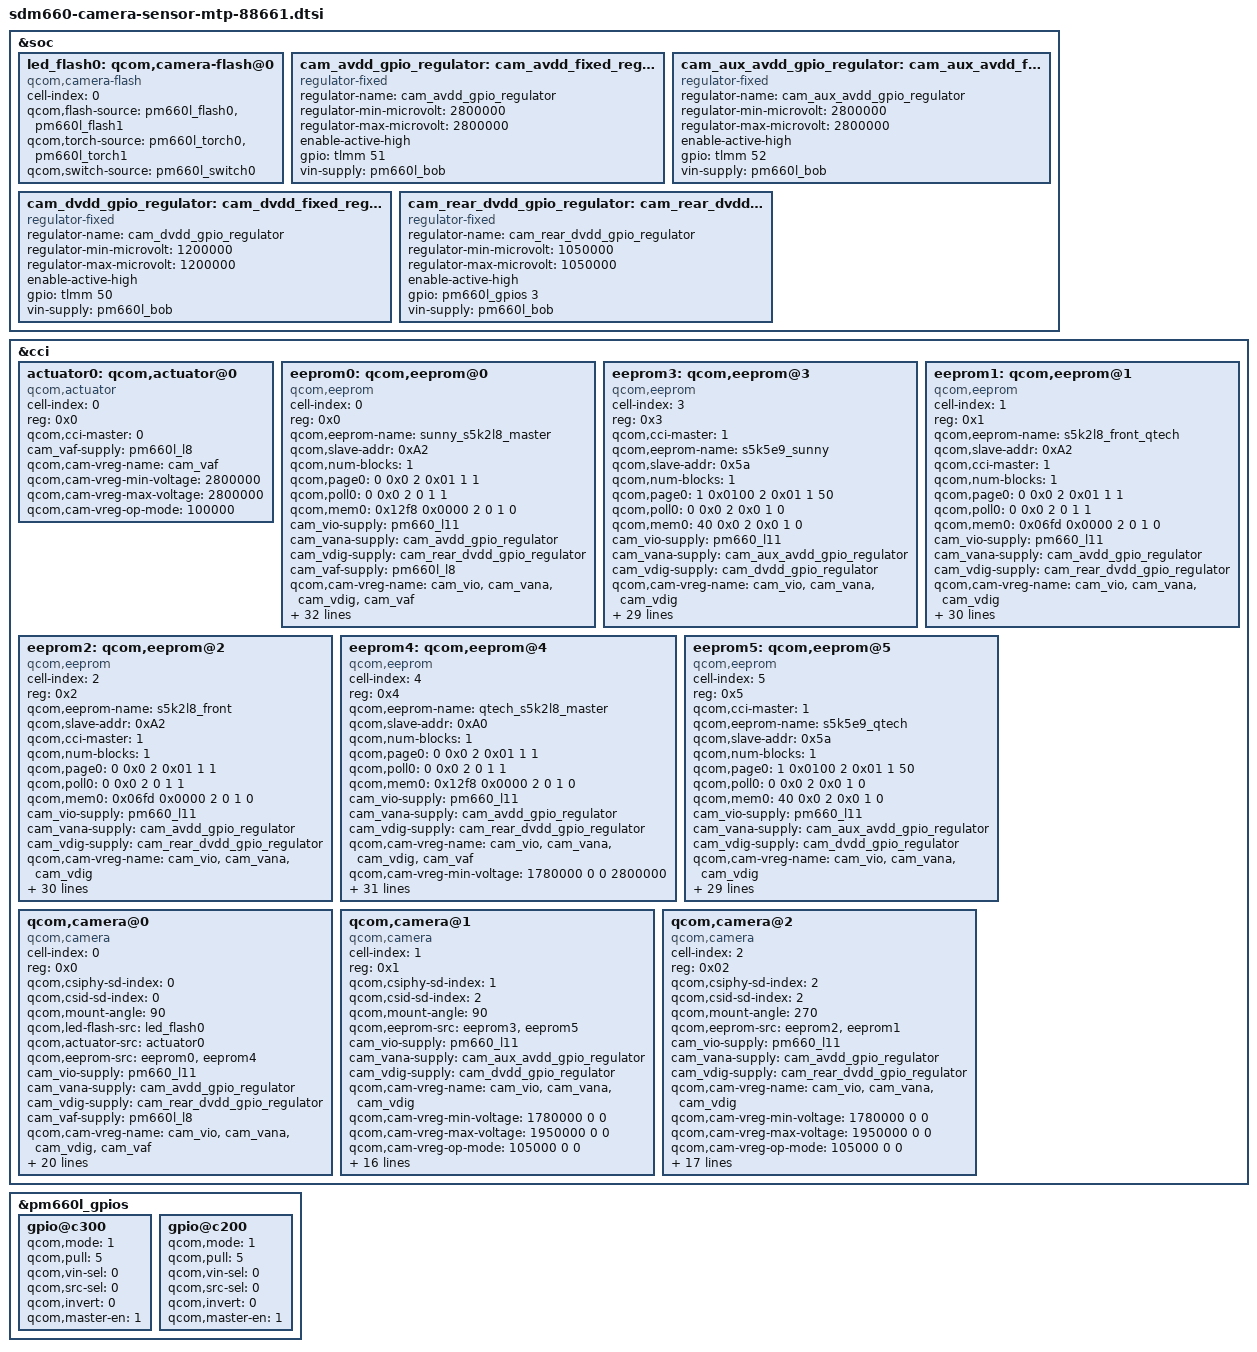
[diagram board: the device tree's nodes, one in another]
/*
 * Copyright (c) 2016-2017, The Linux Foundation. All rights reserved.
 *
 * This program is free software; you can redistribute it and/or modify
 * it under the terms of the GNU General Public License version 2 and
 * only version 2 as published by the Free Software Foundation.
 *
 * This program is distributed in the hope that it will be useful,
 * but WITHOUT ANY WARRANTY; without even the implied warranty of
 * MERCHANTABILITY or FITNESS FOR A PARTICULAR PURPOSE.  See the
 * GNU General Public License for more details.
 */
&soc {
	led_flash0: qcom,camera-flash@0 {
		cell-index = <0>;
		compatible = "qcom,camera-flash";
		qcom,flash-source = <&pm660l_flash0 &pm660l_flash1>;
		qcom,torch-source = <&pm660l_torch0 &pm660l_torch1>;
		qcom,switch-source = <&pm660l_switch0>;
		status = "ok";
	};
	cam_avdd_gpio_regulator: cam_avdd_fixed_regulator {
		compatible = "regulator-fixed";
		regulator-name = "cam_avdd_gpio_regulator";
		regulator-min-microvolt = <2800000>;
		regulator-max-microvolt = <2800000>;
		enable-active-high;
		gpio = <&tlmm 51 0>;
		vin-supply = <&pm660l_bob>;
	};

	cam_aux_avdd_gpio_regulator: cam_aux_avdd_fixed_regulator {
		compatible = "regulator-fixed";
		regulator-name = "cam_aux_avdd_gpio_regulator";
		regulator-min-microvolt = <2800000>;
		regulator-max-microvolt = <2800000>;
		enable-active-high;
		gpio = <&tlmm 52 0>;
		vin-supply = <&pm660l_bob>;
	};
	cam_dvdd_gpio_regulator: cam_dvdd_fixed_regulator {
		compatible = "regulator-fixed";
		regulator-name = "cam_dvdd_gpio_regulator";
		regulator-min-microvolt = <1200000>;
		regulator-max-microvolt = <1200000>;
		enable-active-high;
		gpio = <&tlmm 50 0>;
		vin-supply = <&pm660l_bob>;
	};

	cam_rear_dvdd_gpio_regulator: cam_rear_dvdd_fixed_regulator {
		compatible = "regulator-fixed";
		regulator-name = "cam_rear_dvdd_gpio_regulator";
		regulator-min-microvolt = <1050000>;
		regulator-max-microvolt = <1050000>;
		enable-active-high;
		gpio = <&pm660l_gpios 3 0>;
		vin-supply = <&pm660l_bob>;
	};
};

&cci {
	actuator0: qcom,actuator@0 {
		cell-index = <0>;
		reg = <0x0>;
		compatible = "qcom,actuator";
		qcom,cci-master = <0>;
		cam_vaf-supply = <&pm660l_l8>;
		qcom,cam-vreg-name = "cam_vaf";
		qcom,cam-vreg-min-voltage = <2800000>;
		qcom,cam-vreg-max-voltage = <2800000>;		
		qcom,cam-vreg-op-mode = <100000>;
	};

#if 0
	actuator1: qcom,actuator@1 {
		cell-index = <1>;
		reg = <0x1>;
		compatible = "qcom,actuator";
		qcom,cci-master = <1>;
		cam_vaf-supply = <&cam_actuator_regulator>;
		qcom,cam-vreg-name = "cam_vaf";
		qcom,cam-vreg-min-voltage = <3600000>;
		qcom,cam-vreg-max-voltage = <3600000>;
		qcom,cam-vreg-op-mode = <0>;
	};

	actuator2: qcom,actuator@2 {
		cell-index = <2>;
		reg = <0x2>;
		compatible = "qcom,actuator";
		qcom,cci-master = <1>;
		cam_vaf-supply = <&cam_actuator_regulator>;
		qcom,cam-vreg-name = "cam_vaf";
		qcom,cam-vreg-min-voltage = <3600000>;
		qcom,cam-vreg-max-voltage = <3600000>;
		qcom,cam-vreg-op-mode = <0>;
	};

	ois0: qcom,ois@0 {
		cell-index = <0>;
		reg = <0x0>;
		compatible = "qcom,ois";
		qcom,cci-master = <0>;
		cam_vaf-supply = <&cam_actuator_regulator>;
		qcom,cam-vreg-name = "cam_vaf";
		qcom,cam-vreg-min-voltage = <3600000>;
		qcom,cam-vreg-max-voltage = <3600000>;
		qcom,cam-vreg-op-mode = <0>;
		status = "disabled";
	};

	tof0: qcom,tof@29{
		cell-index = <0>;
		reg = <0x29>;
		compatible = "st,stmvl53l0";
		qcom,cci-master = <0>;
		cam_laser-supply = <&cam_actuator_regulator>;
		qcom,cam-vreg-name =  "cam_laser";
		qcom,cam-vreg-min-voltage = <3600000>;
		qcom,cam-vreg-max-voltage = <3600000>;
		pinctrl-names = "cam_default", "cam_suspend";
		pinctrl-0 = <&cam_tof_active>;
		pinctrl-1 = <&cam_tof_suspend>;
		stm,irq-gpio = <&tlmm 45  0x2008>;
		gpios = <&tlmm 42 0>;
		qcom,gpio-req-tbl-num = <0>;
		qcom,gpio-req-tbl-flags = <0>;
		qcom,gpio-req-tbl-label = "RNG_EN";
	};

	eeprom0: qcom,eeprom@0 {
		cell-index = <0>;
		reg = <0>;
		compatible = "qcom,eeprom";
		cam_vio-supply = <&pm660_l11>;
		cam_vana-supply = <&cam_avdd_gpio_regulator>;
		cam_vdig-supply = <&cam_rear_dvdd_gpio_regulator>;
		qcom,cam-vreg-name = "cam_vio", "cam_vana", "cam_vdig";
		qcom,cam-vreg-min-voltage = <1780000 0 0>;
		qcom,cam-vreg-max-voltage = <1950000 0 0>;
		qcom,cam-vreg-op-mode = <105000 0 0>;
		qcom,gpio-no-mux = <0>;
		pinctrl-names = "cam_default", "cam_suspend";
		pinctrl-0 = <&cam_sensor_mclk0_active
				&cam_sensor_rear_active
				&cam_actuator_vaf_active>;
		pinctrl-1 = <&cam_sensor_mclk0_suspend
				&cam_sensor_rear_suspend
				&cam_actuator_vaf_suspend>;
		gpios = <&tlmm 32 0>,
			<&tlmm 46 0>,
			<&tlmm 50 0>;
		qcom,gpio-reset = <1>;
		qcom,gpio-vaf = <2>;
		qcom,gpio-req-tbl-num = <0 1 2>;
		qcom,gpio-req-tbl-flags = <1 0 0>;
		qcom,gpio-req-tbl-label = "CAMIF_MCLK0",
					"CAM_RESET0",
					"CAM_VAF";
		qcom,sensor-position = <0>;
		qcom,sensor-mode = <0>;
		qcom,cci-master = <0>;
		status = "ok";
		clocks = <&clock_mmss MCLK0_CLK_SRC>,
				<&clock_mmss MMSS_CAMSS_MCLK0_CLK>;
		clock-names = "cam_src_clk", "cam_clk";
		qcom,clock-rates = <24000000 0>;
	};

	eeprom1: qcom,eeprom@1 {
		cell-index = <1>;
		reg = <0x1>;
		compatible = "qcom,eeprom";
		cam_vio-supply = <&pm660_l11>;
		cam_vana-supply = <&cam_avdd_gpio_regulator>;
		cam_vdig-supply = <&cam_dvdd_gpio_regulator>;
		qcom,cam-vreg-name = "cam_vio", "cam_vana", "cam_vdig";
		qcom,cam-vreg-min-voltage = <1780000 0 0>;
		qcom,cam-vreg-max-voltage = <1950000 0 0>;
		qcom,cam-vreg-op-mode = <105000 0 0>;
		qcom,gpio-no-mux = <0>;
		pinctrl-names = "cam_default", "cam_suspend";
		pinctrl-0 = <&cam_sensor_mclk2_active
			&cam_sensor_rear2_active>;
		pinctrl-1 = <&cam_sensor_mclk2_suspend
			&cam_sensor_rear2_suspend>;
		gpios = <&tlmm 34 0>,
		    <&tlmm 48 0>;
		qcom,gpio-reset = <1>;
		qcom,gpio-req-tbl-num = <0 1>;
		qcom,gpio-req-tbl-flags = <1 0>;
		qcom,gpio-req-tbl-label = "CAMIF_MCLK",
				"CAM_RESET";
		qcom,sensor-position = <0>;
		qcom,sensor-mode = <0>;
		qcom,cci-master = <1>;
		status = "ok";
		clocks = <&clock_mmss MCLK2_CLK_SRC>,
		    <&clock_mmss MMSS_CAMSS_MCLK2_CLK>;
		clock-names = "cam_src_clk", "cam_clk";
		qcom,clock-rates = <24000000 0>;
	};

	eeprom2: qcom,eeprom@2 {
		cell-index = <2>;
		reg = <0x2>;
		compatible = "qcom,eeprom";
		cam_vio-supply = <&pm660_l11>;
		cam_vana-supply = <&pm660l_bob>;
		cam_vdig-supply = <&cam_dvdd_gpio_regulator>;
		qcom,cam-vreg-name = "cam_vio", "cam_vana", "cam_vdig";
		qcom,cam-vreg-min-voltage = <1780000 3300000 0>;
		qcom,cam-vreg-max-voltage = <1950000 3600000 0>;
		qcom,cam-vreg-op-mode = <105000 80000 0>;
		qcom,gpio-no-mux = <0>;
		pinctrl-names = "cam_default", "cam_suspend";
		pinctrl-0 = <&cam_sensor_mclk1_active
				 &cam_sensor_front_active
				&cam_actuator_vaf_active>;
		pinctrl-1 = <&cam_sensor_mclk1_suspend
				 &cam_sensor_front_suspend
				&cam_actuator_vaf_suspend>;
		gpios = <&tlmm 33 0>,
			<&tlmm 47 0>,
			<&tlmm 44 0>,
			<&tlmm 50 0>;
		qcom,gpio-reset = <1>;
		qcom,gpio-vana = <2>;
		qcom,gpio-vaf = <3>;
		qcom,gpio-req-tbl-num = <0 1 2 3>;
		qcom,gpio-req-tbl-flags = <1 0 0 0>;
		qcom,gpio-req-tbl-label = "CAMIF_MCLK2",
					"CAM_RESET2",
					"CAM_VANA",
					"CAM_VAF";
		qcom,sensor-position = <1>;
		qcom,sensor-mode = <0>;
		qcom,cci-master = <1>;
		status = "ok";
		clocks = <&clock_mmss MCLK1_CLK_SRC>,
			<&clock_mmss MMSS_CAMSS_MCLK1_CLK>;
		clock-names = "cam_src_clk", "cam_clk";
		qcom,clock-rates = <24000000 0>;
	};
#endif

#if 1
	eeprom0: qcom,eeprom@0 {
		cell-index = <0>;
		reg = <0x0>;
		qcom,eeprom-name = "sunny_s5k2l8_master";
		compatible = "qcom,eeprom";
		qcom,slave-addr = <0xA2>;
		qcom,num-blocks = <1>;
		qcom,page0 = <0 0x0 2 0x01 1 1>;
		qcom,poll0 = <0 0x0 2 0 1 1>;
		qcom,mem0 = <0x12f8 0x0000 2 0 1 0>;
		cam_vio-supply = <&pm660_l11>;
		cam_vana-supply = <&cam_avdd_gpio_regulator>;
		cam_vdig-supply = <&cam_rear_dvdd_gpio_regulator>;
		cam_vaf-supply = <&pm660l_l8>;
		qcom,cam-vreg-name = "cam_vio", "cam_vana", "cam_vdig", "cam_vaf";
		qcom,cam-vreg-min-voltage = <1780000 0 0 2800000>;
		qcom,cam-vreg-max-voltage = <1950000 0 0 2800000>;
		qcom,cam-vreg-op-mode = <105000 0 0 100000>;
		qcom,gpio-no-mux = <0>;
		pinctrl-names = "cam_default", "cam_suspend";
		pinctrl-0 = <&cam_sensor_mclk0_active
				 &cam_sensor_rear_active>;
		pinctrl-1 = <&cam_sensor_mclk0_suspend
				 &cam_sensor_rear_suspend>;
		gpios = <&tlmm 32 0>,
		<&tlmm 46 0>,
		<&pm660l_gpios 3 0>,
		<&tlmm 51 0>;
		qcom,gpio-reset = <1>;
		qcom,gpio-vdig = <2>;
		qcom,gpio-vana = <3>;
		qcom,gpio-req-tbl-num = <0 1 2 3>;
		qcom,gpio-req-tbl-flags = <1 0 0 0>;
		qcom,gpio-req-tbl-label = "CAMIF_MCLK0",
			"CAM_RESET0",
			"CAM_VDIG",
			"CAM_VANA";
		qcom,cam-power-seq-type =
			"sensor_gpio",
			"sensor_vreg",
			"sensor_vreg",
			"sensor_vreg",
			"sensor_vreg",
			"sensor_gpio",
			"sensor_clk";
		qcom,cam-power-seq-val =
			"sensor_gpio_reset",
			"cam_vio",
			"cam_vana",
			"cam_vdig",
			"cam_vaf",
			"sensor_gpio_reset",
			"sensor_cam_mclk";
		qcom,cam-power-seq-cfg-val = <0 1 1 1 1 1 24000000>;
		qcom,cam-power-seq-delay = <5 1 1 5 1 10 10>;
		qcom,sensor-position = <0>;
		qcom,sensor-mode = <0>;
		qcom,cci-master = <0>;
		clocks = <&clock_mmss MCLK0_CLK_SRC>,
		<&clock_mmss MMSS_CAMSS_MCLK0_CLK>;
		clock-names = "cam_src_clk", "cam_clk";
		qcom,clock-rates = <24000000 0>;
	};

	eeprom3: qcom,eeprom@3 {
		cell-index = <3>;
		reg = <0x3>;
		compatible = "qcom,eeprom";
		qcom,cci-master = <1>;
		qcom,eeprom-name = "s5k5e9_sunny";
		qcom,slave-addr = <0x5a>;
		qcom,num-blocks = <1>;
		qcom,page0 = <1 0x0100 2 0x01 1 50>;
		qcom,poll0 = <0 0x0 2 0x0 1 0>;
		qcom,mem0 = <40 0x0 2 0x0 1 0>;
		cam_vio-supply = <&pm660_l11>;
		cam_vana-supply = <&cam_aux_avdd_gpio_regulator>;
		cam_vdig-supply = <&cam_dvdd_gpio_regulator>;
		qcom,cam-vreg-name = "cam_vio", "cam_vana", "cam_vdig";
		qcom,cam-vreg-min-voltage = <1780000 0 0>;
		qcom,cam-vreg-max-voltage = <1950000 0 0>;
		qcom,cam-vreg-op-mode = <105000 0 0>;
		qcom,gpio-no-mux = <0>;
		pinctrl-names = "cam_default", "cam_suspend";
		pinctrl-0 = <&cam_sensor_mclk2_active
				 &cam_sensor_rear2_active>;
		pinctrl-1 = <&cam_sensor_mclk2_suspend
				 &cam_sensor_rear2_suspend>;
		gpios = <&tlmm 34 0>,
		<&tlmm 48 0>,
		<&tlmm 50 0>,
		<&tlmm 52 0>;
		qcom,gpio-reset = <1>;
		qcom,gpio-vdig = <2>;
		qcom,gpio-vana = <3>;
		qcom,gpio-req-tbl-num = <0 1 2 3>;
		qcom,gpio-req-tbl-flags = <1 0 0 0>;
		qcom,gpio-req-tbl-label = "CAMIF_MCLK0",
			"CAM_RESET0",
			"CAM_VDIG",
			"CAM_VANA";
		qcom,cam-power-seq-type =
			"sensor_gpio",
			"sensor_vreg",
			"sensor_vreg",
			"sensor_vreg",
			"sensor_gpio",
			"sensor_clk";
		qcom,cam-power-seq-val =
			"sensor_gpio_reset",
			"cam_vio",
			"cam_vana",
			"cam_vdig",
			"sensor_gpio_reset",
			"sensor_cam_mclk";
		qcom,cam-power-seq-cfg-val = <0 1 1 1 1 24000000>;
		qcom,cam-power-seq-delay = <5 1 1 5 10 10>;
		qcom,sensor-position = <0>;
		qcom,sensor-mode = <0>;
		clocks = <&clock_mmss MCLK2_CLK_SRC>,
		<&clock_mmss MMSS_CAMSS_MCLK2_CLK>;
		clock-names = "cam_src_clk", "cam_clk";
		qcom,clock-rates = <24000000 0>;
	};

	eeprom1: qcom,eeprom@1{
		cell-index = <1>;
		reg = <0x1>;
		qcom,eeprom-name = "s5k2l8_front_qtech";
		compatible = "qcom,eeprom";
		qcom,slave-addr = <0xA2>;
		qcom,cci-master = <1>;
		qcom,num-blocks = <1>;
		qcom,page0 = <0 0x0 2 0x01 1 1>;
		qcom,poll0 = <0 0x0 2 0 1 1>;
		qcom,mem0 = <0x06fd 0x0000 2 0 1 0>;
		cam_vio-supply = <&pm660_l11>;
		cam_vana-supply = <&cam_avdd_gpio_regulator>;
		cam_vdig-supply = <&cam_rear_dvdd_gpio_regulator>;
		qcom,cam-vreg-name = "cam_vio", "cam_vana", "cam_vdig";
		qcom,cam-vreg-min-voltage = <1780000 0 0>;
		qcom,cam-vreg-max-voltage = <1950000 0 0>;
		qcom,cam-vreg-op-mode = <105000 0 0>;
		qcom,gpio-no-mux = <0>;
		pinctrl-names = "cam_default", "cam_suspend";
		pinctrl-0 = <&cam_sensor_mclk1_active
				 &cam_sensor_front_active>;
		pinctrl-1 = <&cam_sensor_mclk1_suspend
				 &cam_sensor_front_suspend>;
		gpios = <&tlmm 33 0>,
		<&tlmm 47 0>,
		<&pm660l_gpios 3 0>,
		<&tlmm 51 0>;
		qcom,gpio-reset = <1>;
		qcom,gpio-vdig = <2>;
		qcom,gpio-vana = <3>;
		qcom,gpio-req-tbl-num = <0 1 2 3>;
		qcom,gpio-req-tbl-flags = <1 0 0 0>;
		qcom,gpio-req-tbl-label = "CAMIF_MCLK2",
			"CAM_RESET2",
			"CAM_VDIG",
			"CAM_VANA";
		qcom,cam-power-seq-type =
			"sensor_gpio",
			"sensor_vreg",
			"sensor_vreg",
			"sensor_vreg",
			"sensor_gpio",
			"sensor_clk";
		qcom,cam-power-seq-val =
			"sensor_gpio_reset",
			"cam_vio",
			"cam_vana",
			"cam_vdig",
			"sensor_gpio_reset",
			"sensor_cam_mclk";
		qcom,cam-power-seq-cfg-val = <0 1 1 1 1 24000000>;
		qcom,cam-power-seq-delay = <5 1 1 5 10 10>;
		qcom,sensor-position = <1>;
		qcom,sensor-mode = <0>;
		status = "ok";
		clocks = <&clock_mmss MCLK1_CLK_SRC>,
			<&clock_mmss MMSS_CAMSS_MCLK1_CLK>;
		clock-names = "cam_src_clk", "cam_clk";
		qcom,clock-rates = <24000000 0>;
	};

	eeprom2: qcom,eeprom@2{
		cell-index = <2>;
		reg = <0x2>;
		qcom,eeprom-name = "s5k2l8_front";
		compatible = "qcom,eeprom";
		qcom,slave-addr = <0xA2>;
		qcom,cci-master = <1>;
		qcom,num-blocks = <1>;
		qcom,page0 = <0 0x0 2 0x01 1 1>;
		qcom,poll0 = <0 0x0 2 0 1 1>;
		qcom,mem0 = <0x06fd 0x0000 2 0 1 0>;
		cam_vio-supply = <&pm660_l11>;
		cam_vana-supply = <&cam_avdd_gpio_regulator>;
		cam_vdig-supply = <&cam_rear_dvdd_gpio_regulator>;
		qcom,cam-vreg-name = "cam_vio", "cam_vana", "cam_vdig";
		qcom,cam-vreg-min-voltage = <1780000 0 0>;
		qcom,cam-vreg-max-voltage = <1950000 0 0>;
		qcom,cam-vreg-op-mode = <105000 0 0>;
		qcom,gpio-no-mux = <0>;
		pinctrl-names = "cam_default", "cam_suspend";
		pinctrl-0 = <&cam_sensor_mclk1_active
				 &cam_sensor_front_active>;
		pinctrl-1 = <&cam_sensor_mclk1_suspend
				 &cam_sensor_front_suspend>;
		gpios = <&tlmm 33 0>,
		<&tlmm 47 0>,
		<&pm660l_gpios 3 0>,
		<&tlmm 51 0>;
		qcom,gpio-reset = <1>;
		qcom,gpio-vdig = <2>;
		qcom,gpio-vana = <3>;
		qcom,gpio-req-tbl-num = <0 1 2 3>;
		qcom,gpio-req-tbl-flags = <1 0 0 0>;
		qcom,gpio-req-tbl-label = "CAMIF_MCLK2",
			"CAM_RESET2",
			"CAM_VDIG",
			"CAM_VANA";
		qcom,cam-power-seq-type =
			"sensor_gpio",
			"sensor_vreg",
			"sensor_vreg",
			"sensor_vreg",
			"sensor_gpio",
			"sensor_clk";
		qcom,cam-power-seq-val =
			"sensor_gpio_reset",
			"cam_vio",
			"cam_vana",
			"cam_vdig",
			"sensor_gpio_reset",
			"sensor_cam_mclk";
		qcom,cam-power-seq-cfg-val = <0 1 1 1 1 24000000>;
		qcom,cam-power-seq-delay = <5 1 1 5 10 10>;
		qcom,sensor-position = <1>;
		qcom,sensor-mode = <0>;
		status = "ok";
		clocks = <&clock_mmss MCLK1_CLK_SRC>,
			<&clock_mmss MMSS_CAMSS_MCLK1_CLK>;
		clock-names = "cam_src_clk", "cam_clk";
		qcom,clock-rates = <24000000 0>;
	};

	eeprom4: qcom,eeprom@4 {
		cell-index = <4>;
		reg = <0x4>;
		qcom,eeprom-name = "qtech_s5k2l8_master";
		compatible = "qcom,eeprom";
		qcom,slave-addr = <0xA0>;
		qcom,num-blocks = <1>;
		qcom,page0 = <0 0x0 2 0x01 1 1>;
		qcom,poll0 = <0 0x0 2 0 1 1>;
		qcom,mem0 = <0x12f8 0x0000 2 0 1 0>;
		cam_vio-supply = <&pm660_l11>;
		cam_vana-supply = <&cam_avdd_gpio_regulator>;
		cam_vdig-supply = <&cam_rear_dvdd_gpio_regulator>;
		qcom,cam-vreg-name = "cam_vio", "cam_vana", "cam_vdig", "cam_vaf";
		qcom,cam-vreg-min-voltage = <1780000 0 0 2800000>;
		qcom,cam-vreg-max-voltage = <1950000 0 0 2800000>;
		qcom,cam-vreg-op-mode = <105000 0 0 100000>;
		qcom,gpio-no-mux = <0>;
		pinctrl-names = "cam_default", "cam_suspend";
		pinctrl-0 = <&cam_sensor_mclk0_active
				 &cam_sensor_rear_active>;
		pinctrl-1 = <&cam_sensor_mclk0_suspend
				 &cam_sensor_rear_suspend>;
		gpios = <&tlmm 32 0>,
		<&tlmm 46 0>,
		<&pm660l_gpios 3 0>,
		<&tlmm 51 0>;
		qcom,gpio-reset = <1>;
		qcom,gpio-vdig = <2>;
		qcom,gpio-vana = <3>;
		qcom,gpio-req-tbl-num = <0 1 2 3>;
		qcom,gpio-req-tbl-flags = <1 0 0 0>;
		qcom,gpio-req-tbl-label = "CAMIF_MCLK0",
			"CAM_RESET0",
			"CAM_VDIG",
			"CAM_VANA";
		qcom,cam-power-seq-type =
			"sensor_gpio",
			"sensor_vreg",
			"sensor_vreg",
			"sensor_vreg",
			"sensor_vreg",
			"sensor_gpio",
			"sensor_clk";
		qcom,cam-power-seq-val =
			"sensor_gpio_reset",
			"cam_vio",
			"cam_vana",
			"cam_vdig",
			"cam_vaf",
			"sensor_gpio_reset",
			"sensor_cam_mclk";
		qcom,cam-power-seq-cfg-val = <0 1 1 1 1 1 24000000>;
		qcom,cam-power-seq-delay = <5 1 1 5 1 10 10>;
		qcom,sensor-position = <0>;
		qcom,sensor-mode = <0>;
		qcom,cci-master = <0>;
		clocks = <&clock_mmss MCLK0_CLK_SRC>,
		<&clock_mmss MMSS_CAMSS_MCLK0_CLK>;
		clock-names = "cam_src_clk", "cam_clk";
		qcom,clock-rates = <24000000 0>;
	};

	eeprom5: qcom,eeprom@5 {
		cell-index = <5>;
		reg = <0x5>;
		compatible = "qcom,eeprom";
		qcom,cci-master = <1>;
		qcom,eeprom-name = "s5k5e9_qtech";
		qcom,slave-addr = <0x5a>;
		qcom,num-blocks = <1>;
		qcom,page0 = <1 0x0100 2 0x01 1 50>;
		qcom,poll0 = <0 0x0 2 0x0 1 0>;
		qcom,mem0 = <40 0x0 2 0x0 1 0>;
		cam_vio-supply = <&pm660_l11>;
		cam_vana-supply = <&cam_aux_avdd_gpio_regulator>;
		cam_vdig-supply = <&cam_dvdd_gpio_regulator>;
		qcom,cam-vreg-name = "cam_vio", "cam_vana", "cam_vdig";
		qcom,cam-vreg-min-voltage = <1780000 0 0>;
		qcom,cam-vreg-max-voltage = <1950000 0 0>;
		qcom,cam-vreg-op-mode = <105000 0 0>;
		qcom,gpio-no-mux = <0>;
		pinctrl-names = "cam_default", "cam_suspend";
		pinctrl-0 = <&cam_sensor_mclk2_active
				 &cam_sensor_rear2_active>;
		pinctrl-1 = <&cam_sensor_mclk2_suspend
				 &cam_sensor_rear2_suspend>;
		gpios = <&tlmm 34 0>,
		<&tlmm 48 0>,
		<&tlmm 50 0>,
		<&tlmm 52 0>;
		qcom,gpio-reset = <1>;
		qcom,gpio-vdig = <2>;
		qcom,gpio-vana = <3>;
		qcom,gpio-req-tbl-num = <0 1 2 3>;
		qcom,gpio-req-tbl-flags = <1 0 0 0>;
		qcom,gpio-req-tbl-label = "CAMIF_MCLK0",
			"CAM_RESET0",
			"CAM_VDIG",
			"CAM_VANA";
		qcom,cam-power-seq-type =
			"sensor_gpio",
			"sensor_vreg",
			"sensor_vreg",
			"sensor_vreg",
			"sensor_gpio",
			"sensor_clk";
		qcom,cam-power-seq-val =
			"sensor_gpio_reset",
			"cam_vio",
			"cam_vana",
			"cam_vdig",
			"sensor_gpio_reset",
			"sensor_cam_mclk";
		qcom,cam-power-seq-cfg-val = <0 1 1 1 1 24000000>;
		qcom,cam-power-seq-delay = <5 1 1 5 10 10>;
		qcom,sensor-position = <0>;
		qcom,sensor-mode = <0>;
		clocks = <&clock_mmss MCLK2_CLK_SRC>,
		<&clock_mmss MMSS_CAMSS_MCLK2_CLK>;
		clock-names = "cam_src_clk", "cam_clk";
		qcom,clock-rates = <24000000 0>;
	};
#endif

	qcom,camera@0 {	
		cell-index = <0>;
		compatible = "qcom,camera";
		reg = <0x0>;
		qcom,csiphy-sd-index = <0>;
		qcom,csid-sd-index = <0>;
		qcom,mount-angle = <90>;
		qcom,led-flash-src = <&led_flash0>;
		qcom,actuator-src = <&actuator0>;
		qcom,eeprom-src = <&eeprom0 &eeprom4>;
		cam_vio-supply = <&pm660_l11>;
		cam_vana-supply = <&cam_avdd_gpio_regulator>;
		cam_vdig-supply = <&cam_rear_dvdd_gpio_regulator>;
		cam_vaf-supply = <&pm660l_l8>;
		qcom,cam-vreg-name = "cam_vio", "cam_vana", "cam_vdig", "cam_vaf";
		qcom,cam-vreg-min-voltage = <1780000 0 0 2800000>;
		qcom,cam-vreg-max-voltage = <1950000 0 0 2800000>;
		qcom,cam-vreg-op-mode = <105000 0 0 100000>;
		qcom,gpio-no-mux = <0>;
		pinctrl-names = "cam_default", "cam_suspend";
		pinctrl-0 = <&cam_sensor_mclk0_active
				 &cam_sensor_rear_active>;
		pinctrl-1 = <&cam_sensor_mclk0_suspend
				 &cam_sensor_rear_suspend>;
		gpios = <&tlmm 32 0>,
			<&tlmm 46 0>;
		qcom,gpio-reset = <1>;
		qcom,gpio-req-tbl-num = <0 1>;
		qcom,gpio-req-tbl-flags = <1 0>;
		qcom,gpio-req-tbl-label = "CAMIF_MCLK0",
					"CAM_RESET0";
		qcom,sensor-position = <0>;
		qcom,sensor-mode = <0>;
		qcom,cci-master = <0>;
		status = "ok";
		clocks = <&clock_mmss MCLK0_CLK_SRC>,
				<&clock_mmss MMSS_CAMSS_MCLK0_CLK>;
		clock-names = "cam_src_clk", "cam_clk";
		qcom,clock-rates = <24000000 0>;
	};

	qcom,camera@1 {
		cell-index = <1>;
		compatible = "qcom,camera";
		reg = <0x1>;
		qcom,csiphy-sd-index = <1>;
		qcom,csid-sd-index = <2>;
		qcom,mount-angle = <90>;
		//qcom,led-flash-src = <&led_flash0>;
		//qcom,actuator-src = <&actuator1>;
		qcom,eeprom-src = <&eeprom3 &eeprom5>;
		cam_vio-supply = <&pm660_l11>;
		cam_vana-supply = <&cam_aux_avdd_gpio_regulator>;
		cam_vdig-supply = <&cam_dvdd_gpio_regulator>;
		qcom,cam-vreg-name = "cam_vio", "cam_vana", "cam_vdig";
		qcom,cam-vreg-min-voltage = <1780000 0 0>;
		qcom,cam-vreg-max-voltage = <1950000 0 0>;
		qcom,cam-vreg-op-mode = <105000 0 0>;
		qcom,gpio-no-mux = <0>;
		pinctrl-names = "cam_default", "cam_suspend";
		pinctrl-0 = <&cam_sensor_mclk2_active
				 &cam_sensor_rear2_active>;
		pinctrl-1 = <&cam_sensor_mclk2_suspend
				 &cam_sensor_rear2_suspend>;
		gpios = <&tlmm 34 0>,
			<&tlmm 48 0>;
		qcom,gpio-reset = <1>;
		qcom,gpio-req-tbl-num = <0 1>;
		qcom,gpio-req-tbl-flags = <1 0>;
		qcom,gpio-req-tbl-label = "CAMIF_MCLK",
					  "CAM_RESET";
		qcom,sensor-position = <0>;
		qcom,sensor-mode = <0>;
		qcom,cci-master = <1>;
		status = "ok";
		clocks = <&clock_mmss MCLK2_CLK_SRC>,
			<&clock_mmss MMSS_CAMSS_MCLK2_CLK>;
		clock-names = "cam_src_clk", "cam_clk";
		qcom,clock-rates = <24000000 0>;
	};

	qcom,camera@2 {
		cell-index = <2>;
		compatible = "qcom,camera";
		reg = <0x02>;
		qcom,csiphy-sd-index = <2>;
		qcom,csid-sd-index = <2>;
		qcom,mount-angle = <270>;
		//qcom,actuator-src = <&actuator2>;
		qcom,eeprom-src = <&eeprom2 &eeprom1>;
		cam_vio-supply = <&pm660_l11>;
		cam_vana-supply = <&cam_avdd_gpio_regulator>;
		cam_vdig-supply = <&cam_rear_dvdd_gpio_regulator>;
		qcom,cam-vreg-name = "cam_vio", "cam_vana", "cam_vdig";
		qcom,cam-vreg-min-voltage = <1780000 0 0>;
		qcom,cam-vreg-max-voltage = <1950000 0 0>;
		qcom,cam-vreg-op-mode = <105000 0 0>;
		qcom,gpio-no-mux = <0>;
		pinctrl-names = "cam_default", "cam_suspend";
		pinctrl-0 = <&cam_sensor_mclk1_active
				 &cam_sensor_front_active>;
		pinctrl-1 = <&cam_sensor_mclk1_suspend
				 &cam_sensor_front_suspend>;
		gpios = <&tlmm 33 0>,
			<&tlmm 47 0>;
		qcom,gpio-reset = <1>;
		qcom,gpio-req-tbl-num = <0 1>;
		qcom,gpio-req-tbl-flags = <1 0>;
		qcom,gpio-req-tbl-label = "CAMIF_MCLK2",
					"CAM_RESET2";
		qcom,sensor-position = <1>;
		qcom,sensor-mode = <0>;
		qcom,cci-master = <1>;
		status = "ok";
		clocks = <&clock_mmss MCLK1_CLK_SRC>,
			<&clock_mmss MMSS_CAMSS_MCLK1_CLK>;
		clock-names = "cam_src_clk", "cam_clk";
		qcom,clock-rates = <24000000 0>;
	};
};

&pm660l_gpios {
	gpio@c300 { /* GPIO4 -CAMERA SENSOR 0 VDIG*/
		qcom,mode = <1>;                /* Output */
		qcom,pull = <5>;                /* No Pull */
		qcom,vin-sel = <0>;             /* VIN1 GPIO_LV */
		qcom,src-sel = <0>;             /* GPIO */
		qcom,invert = <0>;              /* Invert */
		qcom,master-en = <1>;           /* Enable GPIO */
		status = "ok";
	};

	gpio@c200 { /* GPIO3 -CAMERA SENSOR 2 VDIG*/
		qcom,mode = <1>;                /* Output */
		qcom,pull = <5>;                /* No Pull */
		qcom,vin-sel = <0>;             /* VIN1 GPIO_LV */
		qcom,src-sel = <0>;             /* GPIO */
		qcom,invert = <0>;              /* Invert */
		qcom,master-en = <1>;           /* Enable GPIO */
		status = "ok";
	};
};
